# COMPUTE_CLUSTER_ARM_COREPACK_0_COMPUTE_CLUSTER_ARM_COREPACK_0_APBADDR_PMU_CPU1_000730130000h register map
Vendor: Texas Instruments
Peripheral module from a debugger description file (folder am62L).
Registers are 32-bit, read-write, reset 0x0 unless marked. A register's access mark holds for its fields unless they carry their own. Offsets are as the file gives them; lines under a group give offsets from that group; [hi:lo] are bit positions; {n}, {i} and the like mark numbered series; 'fields as' and 'values as' point back to an identical list; <NAME> marks a mode.

## COMPUTE_CLUSTER_ARM_COREPACK_0_APBADDR_PMU_CPU1
{0x0+8i} COMPUTE_CLUSTER_ARM_COREPACK_0_APBADDR_PMU_CPU1_PMEVCNTR{i}_EL0 (i=0..5) — Performance Monitors Event Count Register {i}
  [31:0] PMEVCNTR{i}_EL0 — Event counter n. Value of event counter n, where n is the number of this register and is a number from 0 to 30.
0xF8 COMPUTE_CLUSTER_ARM_COREPACK_0_APBADDR_PMU_CPU1_PMCCNTR_EL0_31_0 — Performance Monitors Cycle Counter (low word)
  [31:0] CCNT — Cycle count. Depending on the values of PMCR_EL0.{LC,D}, the cycle count increments in one of the following ways:Every processor clock cycle.Every 64th processor clock cycle.The cycle count can be reset to zero by Writing 1 to PMCR_EL0.C.
0xFC COMPUTE_CLUSTER_ARM_COREPACK_0_APBADDR_PMU_CPU1_PMCCNTR_EL0_63_32 — Performance Monitors Cycle Counter (high word)
  fields as COMPUTE_CLUSTER_ARM_COREPACK_0_APBADDR_PMU_CPU1_PMCCNTR_EL0_31_0
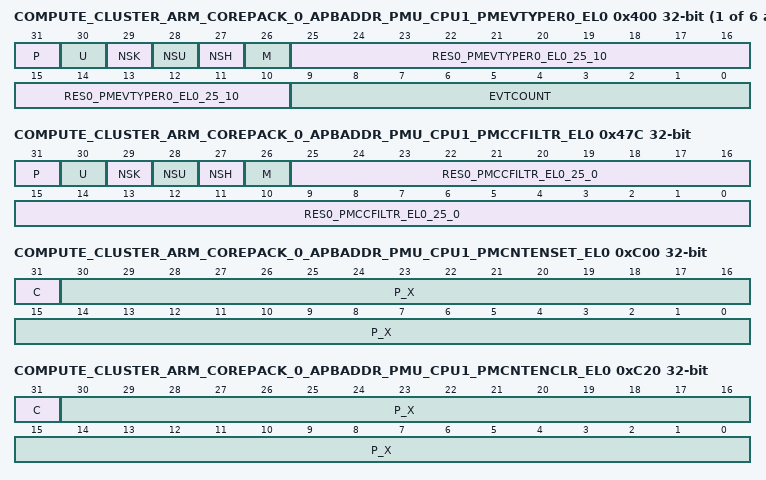
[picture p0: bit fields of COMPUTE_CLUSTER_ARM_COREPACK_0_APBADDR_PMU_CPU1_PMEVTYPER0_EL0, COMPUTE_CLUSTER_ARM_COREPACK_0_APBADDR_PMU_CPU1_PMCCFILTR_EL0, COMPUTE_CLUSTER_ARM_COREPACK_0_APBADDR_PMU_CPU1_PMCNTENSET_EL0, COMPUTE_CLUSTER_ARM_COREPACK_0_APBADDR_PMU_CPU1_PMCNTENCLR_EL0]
{0x400+4i} COMPUTE_CLUSTER_ARM_COREPACK_0_APBADDR_PMU_CPU1_PMEVTYPER{i}_EL0 (i=0..5) — Performance Monitors Event Type Register {i}
  [31] P — EL1 modes filtering bit. Controls counting in EL1. If EL3 is implemented, then counting in Non-secure EL1 is further controlled by the NSK bit. The possible values of this bit are: 0 Count events in EL1. 1 Do not count events in EL1.
  [30] U — EL0 filtering bit. Controls counting in EL0. If EL3 is implemented, then counting in Non-secure EL0 is further controlled by the NSU bit. The possible values of this bit are: 0 Count events in EL0. 1 Do not count events in EL0.
  [29] NSK — Non-secure kernel modes filtering bit. Controls counting in Non-secure EL1. If EL3 is not implemented, this bit is RES0.If the value of this bit is equal to the value of P, events in Non-secure EL1 are counted.Otherwise, events in Non-secure EL1 are not counted.
  [28] NSU — Non-secure user modes filtering bit. Controls counting in Non-secure EL0. If EL3 is not implemented, this bit is RES0.If the value of this bit is equal to the value of U, events in Non-secure EL0 are counted.Otherwise, events in Non-secure EL0 are not counted.
  [27] NSH — Non-secure Hyp modes filtering bit. Controls counting in Non-secure EL2. If EL2 is not implemented, this bit is RES0. 0 Do not count events in EL2. 1 Count events in EL2.
  [26] M — Secure EL3 filtering bit. Most applications can ignore this bit and set the value to zero. If EL3 is not implemented, this bit is RES0.If the value of this bit is equal to the value of P, events in Secure EL3 are counted.Otherwise, events in Secure EL3 are not counted.
  [25:10] RES0_PMEVTYPER{i}_EL0_25_10 — Reserved, RES0.
  [9:0] EVTCOUNT — Event to count. The event number of the event that is counted by event counter PMEVCNTR<n>_EL0.Software must program this field with an event defined by the processor or a common event defined by the architecture.If evtCount is programmed to an event that is reserved or not implemented, the behavior depends on the event type.For common architectural and microarchitectural events:No events are counted.The value read back on evtCount is the value written.For IMPLEMENTATION DEFINED events:It is UNPREDICTABLE what event, if any, is counted. UNPREDICTABLE in this case means the event must not expose privileged information.The value read back on evtCount is an UNKNOWN value with the same effect.ARM recommends that the behavior across a family of implementations is defined such that if a given implementation does not include an event from a set of common IMPLEMENTATION DEFINED events, then no event is counted and the value read back on evtCount is the value written.
0x47C COMPUTE_CLUSTER_ARM_COREPACK_0_APBADDR_PMU_CPU1_PMCCFILTR_EL0 — Performance Monitors Cycle Counter Filter Register
  [31] P — EL1 modes filtering bit. Controls counting in EL1. If EL3 is implemented, then counting in Non-secure EL1 is further controlled by the NSK bit. The possible values of this bit are: 0 Count cycles in EL1. 1 Do not count cycles in EL1.
  [30] U — EL0 filtering bit. Controls counting in EL0. If EL3 is implemented, then counting in Non-secure EL0 is further controlled by the NSU bit. The possible values of this bit are: 0 Count cycles in EL0. 1 Do not count cycles in EL0.
  [29] NSK — Non-secure kernel modes filtering bit. Controls counting in Non-secure EL1. If EL3 is not implemented, this bit is RES0.If the value of this bit is equal to the value of P, cycles in Non-secure EL1 are counted.Otherwise, cycles in Non-secure EL1 are not counted.
  [28] NSU — Non-secure user modes filtering bit. Controls counting in Non-secure EL0. If EL3 is not implemented, this bit is RES0.If the value of this bit is equal to the value of U, cycles in Non-secure EL0 are counted.Otherwise, cycles in Non-secure EL0 are not counted.
  [27] NSH — Non-secure Hyp modes filtering bit. Controls counting in Non-secure EL2. If EL2 is not implemented, this bit is RES0. 0 Do not count cycles in EL2. 1 Count cycles in EL2.
  [26] M — Secure EL3 filtering bit. Most applications can ignore this bit and set the value to zero. If EL3 is not implemented, this bit is RES0.If the value of this bit is equal to the value of P, cycles in Secure EL3 are counted.Otherwise, cycles in Secure EL3 are not counted.
  [25:0] RES0_PMCCFILTR_EL0_25_0 — Reserved, RES0.
0xC00 COMPUTE_CLUSTER_ARM_COREPACK_0_APBADDR_PMU_CPU1_PMCNTENSET_EL0 — Performance Monitors Count Enable Set Register
  [31] C — PMCCNTR_EL0 enable bit. Enables the cycle counter register. Possible values are: 0 When read, means the cycle counter is disabled. When written, has no effect. 1 When read, means the cycle counter is enabled. When written, enables the cycle counter.
  [30:0] P_X — Event counter enable bit for PMEVCNTR<x>.N is the value in PMCR_EL0.N. Bits [30:N] are RAZ/WI.Possible values of each bit are: 0 When read, means that PMEVCNTR<x> is disabled. When written, has no effect. 1 When read, means that PMEVCNTR<x> event counter is enabled. When written, enables PMEVCNTR<x>.
0xC20 COMPUTE_CLUSTER_ARM_COREPACK_0_APBADDR_PMU_CPU1_PMCNTENCLR_EL0 — Performance Monitors Count Enable Clear Register
  [31] C — PMCCNTR_EL0 disable bit. Disables the cycle counter register. Possible values are: 0 When read, means the cycle counter is disabled. When written, has no effect. 1 When read, means the cycle counter is enabled. When written, disables the cycle counter.
  [30:0] P_X — Event counter disable bit for PMEVCNTR<x>.N is the value in PMCR_EL0.N. Bits [30:N] are RAZ/WI.Possible values of each bit are: 0 When read, means that PMEVCNTR<x> is disabled. When written, has no effect. 1 When read, means that PMEVCNTR<x> is enabled. When written, disables PMEVCNTR<x>.
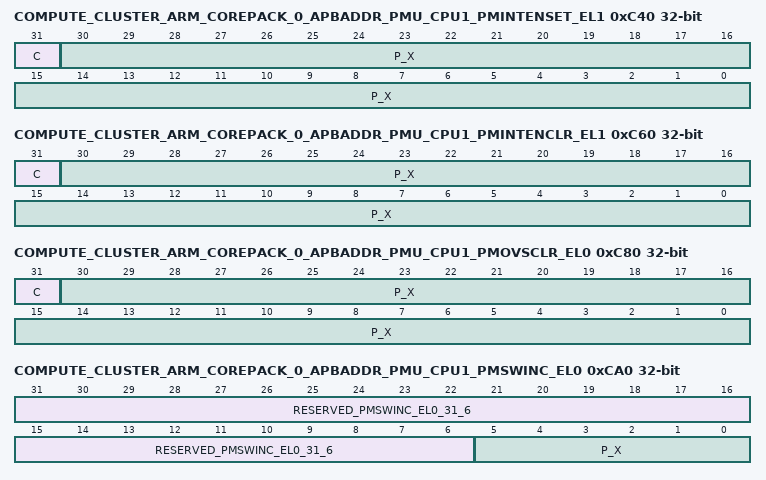
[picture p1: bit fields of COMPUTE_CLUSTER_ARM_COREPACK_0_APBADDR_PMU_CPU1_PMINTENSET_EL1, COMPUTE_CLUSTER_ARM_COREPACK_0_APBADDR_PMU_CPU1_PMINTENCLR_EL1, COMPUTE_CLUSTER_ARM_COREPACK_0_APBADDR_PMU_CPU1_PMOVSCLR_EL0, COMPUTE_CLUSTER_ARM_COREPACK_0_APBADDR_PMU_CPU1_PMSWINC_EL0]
0xC40 COMPUTE_CLUSTER_ARM_COREPACK_0_APBADDR_PMU_CPU1_PMINTENSET_EL1 — Performance Monitors Interrupt Enable Set Register
  [31] C — PMCCNTR_EL0 overflow interrupt request enable bit. Possible values are: 0 When read, means the cycle counter overflow interrupt request is disabled. When written, has no effect. 1 When read, means the cycle counter overflow interrupt request is enabled. When written, enables the cycle count overflow interrupt request.
  [30:0] P_X — Event counter overflow interrupt request enable bit for PMEVCNTR<x>_EL0.N is the value in PMCR_EL0.N. Bits [30:N] are RAZ/WI.Possible values are: 0 When read, means that the PMEVCNTR<x>_EL0 event counter interrupt request is disabled. When written, has no effect. 1 When read, means that the PMEVCNTR<x>_EL0 event counter interrupt request is enabled. When written, enables the PMEVCNTR<x>_EL0 interrupt request.
0xC60 COMPUTE_CLUSTER_ARM_COREPACK_0_APBADDR_PMU_CPU1_PMINTENCLR_EL1 — Performance Monitors Interrupt Enable Clear Register
  [31] C — PMCCNTR_EL0 overflow interrupt request disable bit. Possible values are: 0 When read, means the cycle counter overflow interrupt request is disabled. When written, has no effect. 1 When read, means the cycle counter overflow interrupt request is enabled. When written, disables the cycle count overflow interrupt request.
  [30:0] P_X — Event counter overflow interrupt request disable bit for PMEVCNTR<x>_EL0.N is the value in PMCR_EL0.N. Bits [30:N] are RAZ/WI.Possible values are: 0 When read, means that the PMEVCNTR<x>_EL0 event counter interrupt request is disabled. When written, has no effect. 1 When read, means that the PMEVCNTR<x>_EL0 event counter interrupt request is enabled. When written, disables the PMEVCNTR<x>_EL0 interrupt request.
0xC80 COMPUTE_CLUSTER_ARM_COREPACK_0_APBADDR_PMU_CPU1_PMOVSCLR_EL0 — Performance Monitors Overflow Flag Status Clear Register
  [31] C — PMCCNTR_EL0 overflow bit. Possible values are: 0 When read, means the cycle counter has not overflowed. When written, has no effect. 1 When read, means the cycle counter has overflowed. When written, clears the overflow bit to 0. PMCR_EL0.LC is used to control from which bit of PMCCNTR_EL0 [bit 31 or bit 63] an overflow is detected.
  [30:0] P_X — Event counter overflow clear bit for PMEVCNTR<x>.N is the value in PMCR_EL0.N. Bits [30:N] are RAZ/WI.Possible values of each bit are: 0 When read, means that PMEVCNTR<x> has not overflowed. When written, has no effect. 1 When read, means that PMEVCNTR<x> has overflowed. When written, clears the PMEVCNTR<x> overflow bit to 0.
0xCA0 COMPUTE_CLUSTER_ARM_COREPACK_0_APBADDR_PMU_CPU1_PMSWINC_EL0 — Performance Monitors Software Increment Register
  [31:6] RESERVED_PMSWINC_EL0_31_6 — Reserved RES0
  [5:0] P_X — Event counter software increment bit for PMEVCNTR<x>
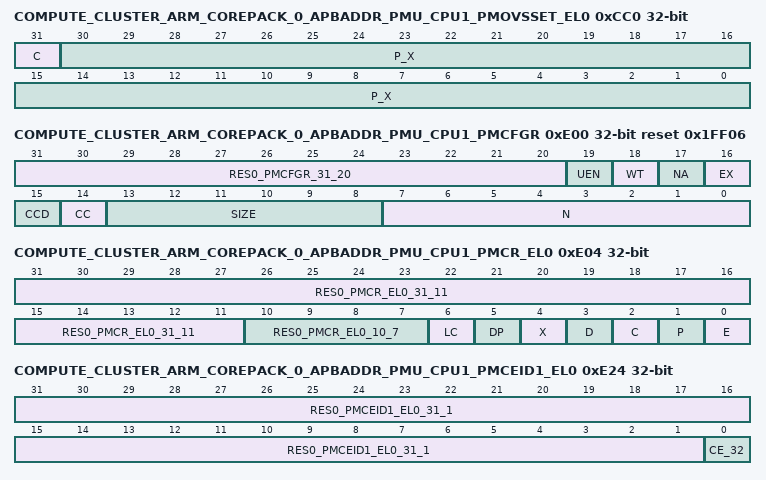
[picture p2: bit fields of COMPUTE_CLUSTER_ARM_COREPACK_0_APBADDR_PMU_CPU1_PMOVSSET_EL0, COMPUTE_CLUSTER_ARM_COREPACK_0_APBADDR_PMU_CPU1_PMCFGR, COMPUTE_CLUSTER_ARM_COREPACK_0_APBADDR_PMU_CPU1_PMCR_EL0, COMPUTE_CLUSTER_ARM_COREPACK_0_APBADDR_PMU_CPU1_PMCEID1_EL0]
0xCC0 COMPUTE_CLUSTER_ARM_COREPACK_0_APBADDR_PMU_CPU1_PMOVSSET_EL0 — Performance Monitors Overflow Flag Status Set Register
  [31] C — PMCCNTR_EL0 overflow bit. Possible values are: 0 When read, means the cycle counter has not overflowed. When written, has no effect. 1 When read, means the cycle counter has overflowed. When written, sets the overflow bit to 1.
  [30:0] P_X — Event counter overflow set bit for PMEVCNTR<x>.N is the value in PMCR_EL0.N. Bits [30:N] are RAZ/WI.Possible values are: 0 When read, means that PMEVCNTR<x> has not overflowed. When written, has no effect. 1 When read, means that PMEVCNTR<x> has overflowed. When written, sets the PMEVCNTR<x> overflow bit to 1.
0xE00 COMPUTE_CLUSTER_ARM_COREPACK_0_APBADDR_PMU_CPU1_PMCFGR reset 0x1FF06 — Performance Monitors Configuration Register
  [31:20] RES0_PMCFGR_31_20 — Reserved, RES0.
  [19] UEN — User-mode Enable Register supported. PMUSERENR_EL0 is not visible in the external debug interface, so this bit is RES0.
  [18] WT — This feature is not supported, so this bit is RES0.
  [17] NA — This feature is not supported, so this bit is RES0.
  [16] EX — Export supported. Value is IMPLEMENTATION DEFINED. 0 PMCR_EL0.X is RES0. 1 PMCR_EL0.X is read/write.
  [15] CCD — Cycle counter has prescale. This is RES1 if AArch32 is supported at any EL, and RES0 otherwise. 0 PMCR_EL0.D is RES0. 1 PMCR_EL0.D is read/write.
  [14] CC — Dedicated cycle counter [counter 31] supported. This bit is RES1.
  [13:8] SIZE — Size of counters. This field determines the spacing of counters in the memory-map.In v8-A the counters are at doubleword-aligned addresses, and the largest counter is 64-bits, so this field is 0b111111.
  [7:0] N — Number of counters implemented in addition to the cycle counter, PMCCNTR_EL0. The maximum number of event counters is 31, so bits[7:5] are always RES0. 00000000 Only PMCCNTR_EL0 implemented. 00000001 PMCCNTR_EL0 plus one event counter implemented. and so on up to 0b00011111, which indicates PMCCNTR_EL0 and 31 event counters implemented.
0xE04 COMPUTE_CLUSTER_ARM_COREPACK_0_APBADDR_PMU_CPU1_PMCR_EL0 — Performance Monitors Control Register
  [31:11] RES0_PMCR_EL0_31_11 — Reserved, RAZ/WI.
  [10:7] RES0_PMCR_EL0_10_7 — Reserved, RES0.
  [6] LC — Long cycle counter enable. Determines which PMCCNTR_EL0 bit generates an overflow recorded by PMOVSR[31]. 0 Cycle counter overflow on increment that changes PMCCNTR_EL0[31] from 1 to 0. 1 Cycle counter overflow on increment that changes PMCCNTR_EL0[63] from 1 to 0. ARM deprecates use of PMCR_EL0.LC = 0.
  [5] DP — Disable cycle counter when event counting is prohibited. The possible values of this bit are: 0 PMCCNTR_EL0, if enabled, counts when event counting is prohibited. 1 PMCCNTR_EL0 does not count when event counting is prohibited. Event counting is prohibited when ProfilingProhibited[IsSecure[],PSTATE.EL] == TRUE.This bit is RW.
  [4] X — Enable export of events in an IMPLEMENTATION DEFINED event stream. The possible values of this bit are: 0 Do not export events. 1 Export events where not prohibited. This bit is used to permit events to be exported to another debug device, such as an OPTIONAL trace extension, over an event bus. If the implementation does not include such an event bus, this bit is RAZ/WI.This bit does not affect the generation of Performance Monitors overflow interrupt requests or signaling to a cross-trigger interface [CTI] that can be implemented as signals exported from the processor.If the implementation does not include an exported event stream, this bit is RAZ/WI. Otherwise this bit is RW.
  [3] D — Clock divider. The possible values of this bit are: 0 When enabled, PMCCNTR_EL0 counts every clock cycle. 1 When enabled, PMCCNTR_EL0 counts once every 64 clock cycles. This bit is RW.If PMCR_EL0.LC == 1, this bit is ignored and the cycle counter counts every clock cycle.ARM deprecates use of PMCR.D = 1.
  [2] C — Cycle counter reset. This bit is WO. The effects of Writing to this bit are: 0 No action. 1 Reset PMCCNTR_EL0 to zero. This bit is always RAZ.Resetting PMCCNTR_EL0 does not clear the PMCCNTR_EL0 overflow bit to 0.
  [1] P — Event counter reset. This bit is WO. The effects of Writing to this bit are: 0 No action. 1 Reset all event counters, not including PMCCNTR_EL0, to zero. This bit is always RAZ.Resetting the event counters does not clear any overflow bits to 0.
  [0] E — Enable. The possible values of this bit are: 0 All counters, including PMCCNTR_EL0, are disabled. 1 All counters are enabled by PMCNTENSET_EL0. This bit is RW.
0xE20 COMPUTE_CLUSTER_ARM_COREPACK_0_APBADDR_PMU_CPU1_PMCEID0_EL0 reset 0x67FFBFFF — Performance Monitors Common Event Identification Register 0
  [31:0] CE_31_0 — Common architectural and microarchitectural feature events that can be counted by the PMU event counters.For each bit described in the following table, the event is implemented if the bit is set to 1, or not implemented if the bit is set to 0.BitEvent numberEvent mnemonic310x01FL1D_CACHE_ALLOCATE300x01ECHAIN290x01DBUS_CYCLES280x01CTTBR_WRITE_RETIRED270x01BINST_SPEC260x01AMEMORY_ERROR250x019BUS_ACCESS240x018L2D_CACHE_WB230x017L2D_CACHE_REFILL220x016L2D_CACHE210x015L1D_CACHE_WB200x014L1I_CACHE190x013MEM_ACCESS180x012BR_PRED170x011CPU_CYCLES160x010BR_MIS_PRED150x00FUNALIGNED_LDST_RETIRED140x00EBR_RETURN_RETIRED130x00DBR_IMMED_RETIRED120x00CPC_WRITE_RETIRED110x00BCID_WRITE_RETIRED100x00AEXC_RETURN90x009EXC_TAKEN80x008INST_RETIRED70x007ST_RETIRED60x006LD_RETIRED50x005L1D_TLB_REFILL40x004L1D_CACHE30x003L1D_CACHE_REFILL20x002L1I_TLB_REFILL10x001L1I_CACHE_REFILL00x000SW_INCR
0xE24 COMPUTE_CLUSTER_ARM_COREPACK_0_APBADDR_PMU_CPU1_PMCEID1_EL0 — Performance Monitors Common Event Identification Register 1
  [31:1] RES0_PMCEID1_EL0_31_1 — Reserved, RES0.
  [0] CE_32 — Common architectural and microarchitectural feature events that can be counted by the PMU event counters.For the bit described in the following table, the event is implemented if the bit is set to 1, or not implemented if the bit is set to 0.BitEvent numberEvent mnemonic00x020L2D_CACHE_ALLOCATE
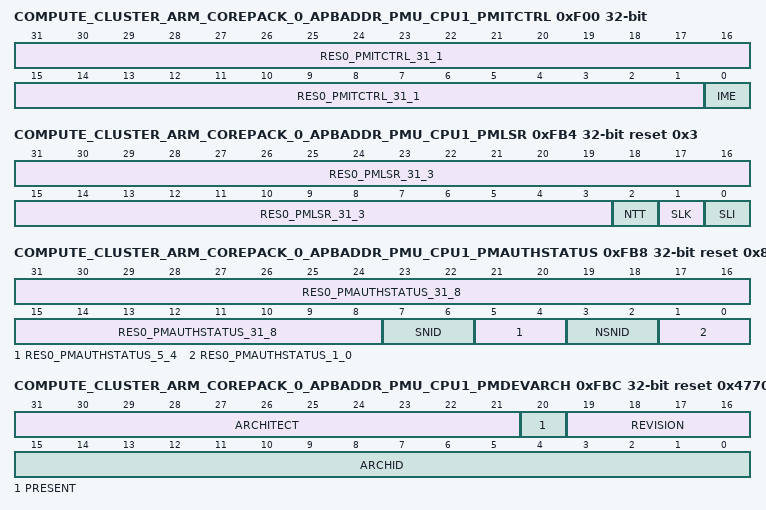
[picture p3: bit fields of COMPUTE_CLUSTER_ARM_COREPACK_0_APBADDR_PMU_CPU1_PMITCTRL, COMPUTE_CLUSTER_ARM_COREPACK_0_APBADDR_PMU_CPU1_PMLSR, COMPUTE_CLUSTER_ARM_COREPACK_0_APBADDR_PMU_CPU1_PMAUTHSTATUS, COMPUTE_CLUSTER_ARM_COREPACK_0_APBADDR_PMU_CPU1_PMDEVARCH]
0xF00 COMPUTE_CLUSTER_ARM_COREPACK_0_APBADDR_PMU_CPU1_PMITCTRL — Performance Monitors Integration mode Control Register
  [31:1] RES0_PMITCTRL_31_1 — Reserved, RES0.
  [0] IME — Integration mode enable. When IME == 1, the device reverts to an integration mode to enable integration testing or topology detection. The integration mode behavior is IMPLEMENTATION DEFINED. 0 Normal operation. 1 Integration mode enabled.
0xFA8 COMPUTE_CLUSTER_ARM_COREPACK_0_APBADDR_PMU_CPU1_PMDEVAFF0 reset 0x80000001 — Performance Monitors Device Affinity Register 0
  [31:0] PMDEVAFF0 — MPIDR_EL1 low half. Read-only copy of the low half of MPIDR_EL1, as seen from the highest implemented exception level.
0xFAC COMPUTE_CLUSTER_ARM_COREPACK_0_APBADDR_PMU_CPU1_PMDEVAFF1 — Performance Monitors Device Affinity Register 1
  [31:0] PMDEVAFF1 — MPIDR_EL1 high half. Read-only copy of the high half of MPIDR_EL1, as seen from the highest implemented exception level.
0xFB0 COMPUTE_CLUSTER_ARM_COREPACK_0_APBADDR_PMU_CPU1_PMLAR — Performance Monitors Lock Access Register
  [31:0] KEY — Lock Access control. Writing the key value 0xC5ACCE55 to this field unlocks the lock, enabling write accesses to this component's registers through a memory-mapped interface.Writing any other value to this register locks the lock, disabling write accesses to this component's registers through a memory mapped interface.
0xFB4 COMPUTE_CLUSTER_ARM_COREPACK_0_APBADDR_PMU_CPU1_PMLSR reset 0x3 — Performance Monitors Lock Status Register
  [31:3] RES0_PMLSR_31_3 — Reserved, RES0.
  [2] NTT — Not thirty-two bit access required. RAZ.
  [1] SLK — Software lock status for this component. For an access to LSR that is not a memory-mapped access, or when the software lock is not implemented, this field is RES0.For memory-mapped accesses when the software lock is implemented, possible values of this field are: 0 Lock clear. Writes are permitted to this component's registers. 1 Lock set. Writes to this component's registers are ignored, and reads have no side effects.
  [0] SLI — Software lock implemented. For an access to LSR that is not a memory-mapped access, this field is RAZ. For memory-mapped accesses, the value of this field is IMPLEMENTATION DEFINED. Permitted values are: 0 Software lock not implemented or not memory-mapped access. 1 Software lock implemented and memory-mapped access.
0xFB8 COMPUTE_CLUSTER_ARM_COREPACK_0_APBADDR_PMU_CPU1_PMAUTHSTATUS reset 0x88 — Performance Monitors Authentication Status Register
  [31:8] RES0_PMAUTHSTATUS_31_8 — Reserved, RES0.
  [7:6] SNID — Holds the same value as DBGAUTHSTATUS_EL1.SNID.
  [5:4] RES0_PMAUTHSTATUS_5_4 — Reserved, RES0.
  [3:2] NSNID — Holds the same value as DBGAUTHSTATUS_EL1.NSNID.
  [1:0] RES0_PMAUTHSTATUS_1_0 — Reserved, RES0.
0xFBC COMPUTE_CLUSTER_ARM_COREPACK_0_APBADDR_PMU_CPU1_PMDEVARCH reset 0x47702A16 — Performance Monitors Device Architecture Register
  [31:21] ARCHITECT — Defines the architecture of the component. For Performance Monitors, this is ARM Limited.Bits [31:28] are the JEP 106 continuation code, 0x4.Bits [27:21] are the JEP 106 ID code, 0x3B.
  [20] PRESENT — When set to 1, indicates that the DEVARCH is present.This field is 1 in v8-A.
  [19:16] REVISION — Defines the architecture revision. For architectures defined by ARM this is the minor revision.For Performance Monitors, the revision defined by v8-A is 0x0.All other values are reserved.
  [15:0] ARCHID — Defines this part to be a v8-A debug component. For architectures defined by ARM this is further subdivided.For Performance Monitors:Bits [15:12] are the architecture version, 0x2.Bits [11:0] are the architecture part number, 0xA16.This corresponds to Performance Monitors architecture version PMUv3.
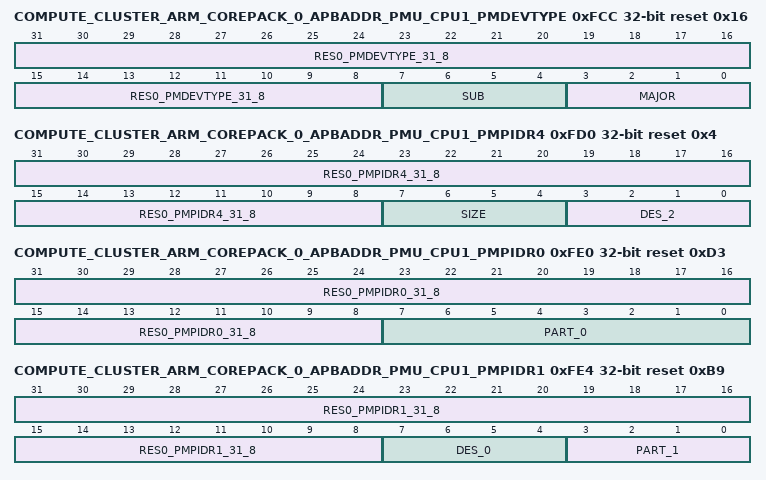
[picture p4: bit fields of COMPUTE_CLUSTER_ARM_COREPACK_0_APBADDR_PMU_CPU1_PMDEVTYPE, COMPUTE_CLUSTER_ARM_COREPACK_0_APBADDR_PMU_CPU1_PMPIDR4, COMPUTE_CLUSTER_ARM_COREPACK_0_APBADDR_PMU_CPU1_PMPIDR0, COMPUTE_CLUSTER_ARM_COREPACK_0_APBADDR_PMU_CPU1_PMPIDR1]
0xFCC COMPUTE_CLUSTER_ARM_COREPACK_0_APBADDR_PMU_CPU1_PMDEVTYPE reset 0x16 — Performance Monitors Device Type Register
  [31:8] RES0_PMDEVTYPE_31_8 — Reserved, RES0.
  [7:4] SUB — Subtype. Must read as 0x1 to indicate this is a processor component.
  [3:0] MAJOR — Major type. Must read as 0x6 to indicate this is a performance monitor component.
0xFD0 COMPUTE_CLUSTER_ARM_COREPACK_0_APBADDR_PMU_CPU1_PMPIDR4 reset 0x4 — Performance Monitors Peripheral Identification Register 4
  [31:8] RES0_PMPIDR4_31_8 — Reserved, RES0.
  [7:4] SIZE — Size of the component. RAZ. Log2 of the number of 4KB pages from the start of the component to the end of the component ID registers.
  [3:0] DES_2 — Designer, JEP106 continuation code, least significant nibble. For ARM Limited, this field is 0b0100.
{0xFC0+4i} COMPUTE_CLUSTER_ARM_COREPACK_0_APBADDR_PMU_CPU1_PMPIDR{i} (i=5..7) — Performance Monitors Peripheral Identification Register {i}
  [31:0] RESERVED_PMPIDR{i}_31_0 — Reserved RES0
0xFE0 COMPUTE_CLUSTER_ARM_COREPACK_0_APBADDR_PMU_CPU1_PMPIDR0 reset 0xD3 — Performance Monitors Peripheral Identification Register 0
  [31:8] RES0_PMPIDR0_31_8 — Reserved, RES0.
  [7:0] PART_0 — Part number, least significant byte.
0xFE4 COMPUTE_CLUSTER_ARM_COREPACK_0_APBADDR_PMU_CPU1_PMPIDR1 reset 0xB9 — Performance Monitors Peripheral Identification Register 1
  [31:8] RES0_PMPIDR1_31_8 — Reserved, RES0.
  [7:4] DES_0 — Designer, least significant nibble of JEP106 ID code. For ARM Limited, this field is 0b1011.
  [3:0] PART_1 — Part number, most significant nibble.
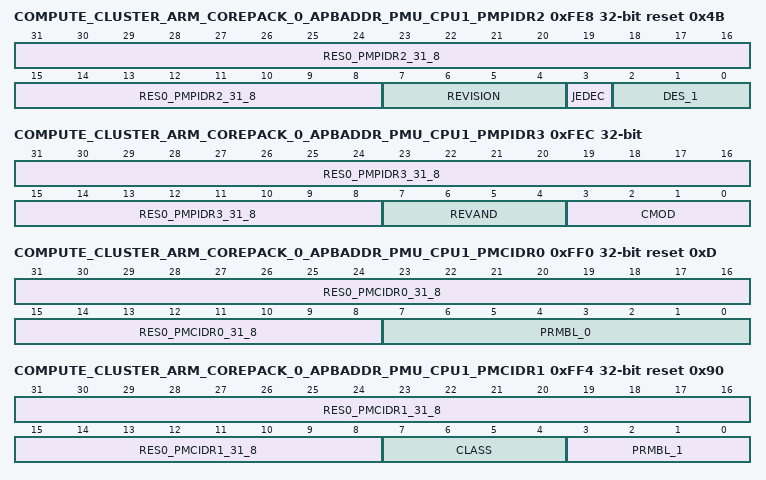
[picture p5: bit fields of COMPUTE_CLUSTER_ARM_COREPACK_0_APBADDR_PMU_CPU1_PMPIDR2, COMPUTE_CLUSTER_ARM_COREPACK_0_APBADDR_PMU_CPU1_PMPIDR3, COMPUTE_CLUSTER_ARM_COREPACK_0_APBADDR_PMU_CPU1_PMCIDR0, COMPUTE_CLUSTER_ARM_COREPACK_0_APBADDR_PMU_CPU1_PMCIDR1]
0xFE8 COMPUTE_CLUSTER_ARM_COREPACK_0_APBADDR_PMU_CPU1_PMPIDR2 reset 0x4B — Performance Monitors Peripheral Identification Register 2
  [31:8] RES0_PMPIDR2_31_8 — Reserved, RES0.
  [7:4] REVISION — Part major revision. Parts can also use this field to extend Part number to 16-bits.
  [3] JEDEC — RAO. Indicates a JEP106 identity code is used.
  [2:0] DES_1 — Designer, most significant bits of JEP106 ID code. For ARM Limited, this field is 0b011.
0xFEC COMPUTE_CLUSTER_ARM_COREPACK_0_APBADDR_PMU_CPU1_PMPIDR3 — Performance Monitors Peripheral Identification Register 3
  [31:8] RES0_PMPIDR3_31_8 — Reserved, RES0.
  [7:4] REVAND — Part minor revision. Parts using PMPIDR2.REVISION as an extension to the Part number must use this field as a major revision number.
  [3:0] CMOD — Customer modified. Indicates someone other than the Designer has modified the component.
0xFF0 COMPUTE_CLUSTER_ARM_COREPACK_0_APBADDR_PMU_CPU1_PMCIDR0 reset 0xD — Performance Monitors Component Identification Register 0
  [31:8] RES0_PMCIDR0_31_8 — Reserved, RES0.
  [7:0] PRMBL_0 — Preamble. Must read as 0x0D.
0xFF4 COMPUTE_CLUSTER_ARM_COREPACK_0_APBADDR_PMU_CPU1_PMCIDR1 reset 0x90 — Performance Monitors Component Identification Register 1
  [31:8] RES0_PMCIDR1_31_8 — Reserved, RES0.
  [7:4] CLASS — Component class. Reads as 0x9, debug component.
  [3:0] PRMBL_1 — Preamble. RAZ.
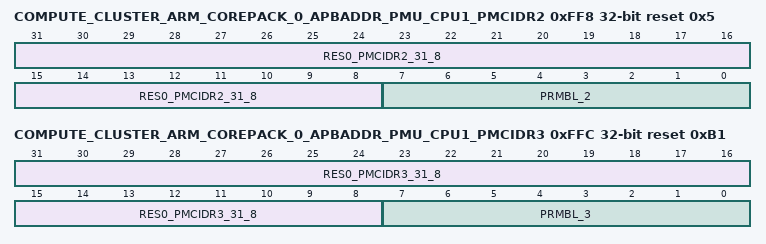
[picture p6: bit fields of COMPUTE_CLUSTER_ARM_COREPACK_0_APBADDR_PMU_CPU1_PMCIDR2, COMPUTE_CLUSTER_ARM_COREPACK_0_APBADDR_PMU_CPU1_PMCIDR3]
0xFF8 COMPUTE_CLUSTER_ARM_COREPACK_0_APBADDR_PMU_CPU1_PMCIDR2 reset 0x5 — Performance Monitors Component Identification Register 2
  [31:8] RES0_PMCIDR2_31_8 — Reserved, RES0.
  [7:0] PRMBL_2 — Preamble. Must read as 0x05.
0xFFC COMPUTE_CLUSTER_ARM_COREPACK_0_APBADDR_PMU_CPU1_PMCIDR3 reset 0xB1 — Performance Monitors Component Identification Register 3
  [31:8] RES0_PMCIDR3_31_8 — Reserved, RES0.
  [7:0] PRMBL_3 — Preamble. Must read as 0xB1.
